# tviic2d6mddr register map
Vendor: Cypress Semiconductor; Series: tviic2d6mddr; File version: 1.0
CPU: CM7 r0p1, little endian, MPU, FPU, VTOR, 3 interrupt priority bits
Registers are 32-bit, read-write, reset 0x0 unless marked. A register's access mark holds for its fields unless they carry their own. Offsets are from the block's base; [hi:lo] are bit positions; lines under a group give offsets from that group; {n}, {i} and the like mark numbered series.

## JPEGDEC
Base 0x40B10000
0x00 CTL — IP control register.
  [31] ENABLED — IP enable. When the IP is disabled, no other register than this one can be accessed (results in AHB error response). 0: Disabled. 1: Enabled.
0x1000 HF group — Data fetch, store and interrupt control registers.
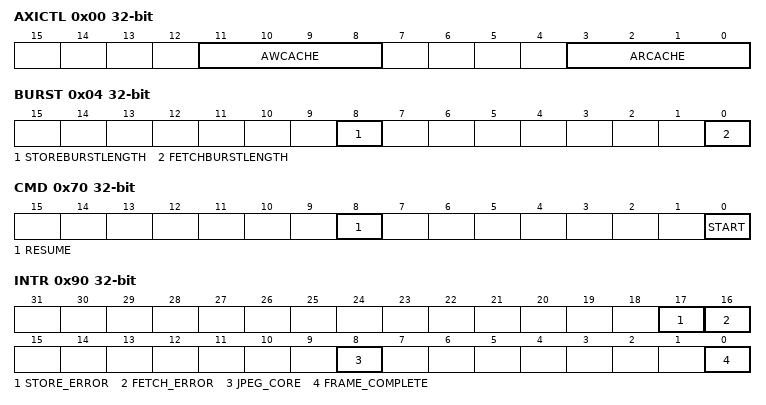
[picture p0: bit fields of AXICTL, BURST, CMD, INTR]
  0x00 AXICTL — AXI cache attributes.
    [11:8] AWCACHE — AWCACHE value of AXI transactions on Store Unit. Must not be changed during decoding operation.
    [3:0] ARCACHE — ARCACHE value of AXI transactions on Fetch Unit. Must not be changed during decoding operation.
  0x04 BURST — AXI burst settings.
    [8] STOREBURSTLENGTH — Maximum burst length for Store Unit. Must not be changed during decoding operation. 0: Length is 4 1: Length is 8
    [0] FETCHBURSTLENGTH — Maximum burst length for Fetch Unit. Must not be changed during decoding operation. 0: Length is 4 1: Length is 8
  0x10 FETCHBUF0 — Source buffer configuration (JPEG).
    [31:0] FETCHBASEADDRESS — Start address of the JPEG image in bytes. There are no alignment restrictions, however, read access to memory is 32- or 64-byte aligned, depending on configured burst length. So reading ahead of the actual start address must be allowed, if it is not aligned accordingly. RWS field, which is activated by START command.
  0x14 FETCHBUF1 — Source buffer configuration (JPEG).
    [29:0] FETCHLENGTH — JPEG image length in bytes. There are no alignment restrictions, however, read access to memory is 32- or 64-byte aligned, depending on the configured burst length. So reading beyond the actual end address must be allowed, if it is not aligned accordingly. RWS field, which is activated by START command.
  0x20 STORE0BUF0 — Destination buffer configuration (Y, YUV, RGB).
    [31:6] STOREBASEADDRESS0 — Start address of the destination buffer 0 in multiple of 64 bytes. The destination buffer 0 holds the YUV or RGB pixels for packed format and Y pixels only for semi-planar format. RWS field, which is activated by START or RESUME command.
  0x24 STORE0BUF1 — Destination buffer configuration (Y, YUV, RGB).
    [31:6] STORESTRIDE0 — Line stride of the destination buffer 0 in multiple of 64 bytes. RWS field, which is activated by START or RESUME command.
  0x28 STORE0BUF2 — Destination buffer configuration (Y, YUV, RGB).
    [31:6] STORELENGTH0 — Destination buffer 0 length in multiple of 64 bytes. RWS field, which is activated by START or RESUME command.
  0x40 STORE1BUF0 — Destination buffer configuration (UV).
    [31:6] STOREBASEADDRESS1 — Start address of the destination buffer 1 in multiple of 64 bytes. The destination buffer 1 holds UV pixels for semi-planar format. RWS field, which is activated by START or RESUME command.
  0x44 STORE1BUF1 — Destination buffer configuration (UV).
    [31:6] STORESTRIDE1 — Line stride of the destination buffer 1 in multiple of 64 bytes.RWS field, which is activated by START or RESUME command.
  0x48 STORE1BUF2 — Destination buffer configuration (UV).
    [31:6] STORELENGTH1 — Destination buffer 1 length in multiple of 64 bytes. RWS field, which is activated by START or RESUME command.
  0x60 STORECTL — Destination buffer format settings.
    [0] UPSAMPLING — Decoded pixels are up-sampled to YUV 4:4:4. If the sub-sampling mode in the encoded JPEG data is NOT YUV 4:2:2, YUV 4:1:1 or YUV 4:2:0, this field is ignored. RWS field, which is activated by START or RESUME command.
  0x70 CMD — Start/Resume triggers.
    [8] RESUME — Writing '1' to this register will activate store related shadow configuration (RWS) and then resume a suspended decoding operation.
    [0] START — Writing '1' to this register will activate fetch and store related shadow configuration (RWS) and then start a new decoding operation. The following registers are initialized by this operation: ERRORSTATUS STORESTATUS FETCHSTATUS DECODINGSTATUS INTR_DEC ERRORCODE CORRECTIONCROPSTATUS SUSPEND DNL DRI (only if DECODINGOPTION.MARKERSKIP=0) All Huffman Tables (only if DECODINGOPTION.MARKERSKIP=0)
  0x80 DECODEINTRMASK — Decoder core decoding end interrupt mask.
    [0] DECODEINTRMASK — Setting this bit to '1' propagates decoding completion status (INTR_DEC.NORMALEND/INTR_DEC.CORRECTEDEND ORed) to INTR.JPEG_CORE.
  0x90 INTR — Interrupt status bits.
    [17] STORE_ERROR — HW sets this field to '1' when there is an error in the on-going AXI transaction on store side (i.e. when one of ERRORSTATUS fields is set). Read ERRORSTATUS to see what event set this bit.
    [16] FETCH_ERROR — HW sets this field to '1' when there is an error in the on-going AXI transaction on fetch side (i.e. when one of ERRORSTATUS fields is set). Read ERRORSTATUS to see what event set this bit.
    [8] JPEG_CORE — HW sets this field to '1' when a flag in INTR_DEC is set with corresponding propagation field enabled (DECODEINTRMASK or INTR_DEC_EN). See description of INTR_DEC_EN/DECODEINTRMASK for more detail.
    [0] FRAME_COMPLETE — This interrupt occurs when Store Unit finishes storing all pixels in the destination.
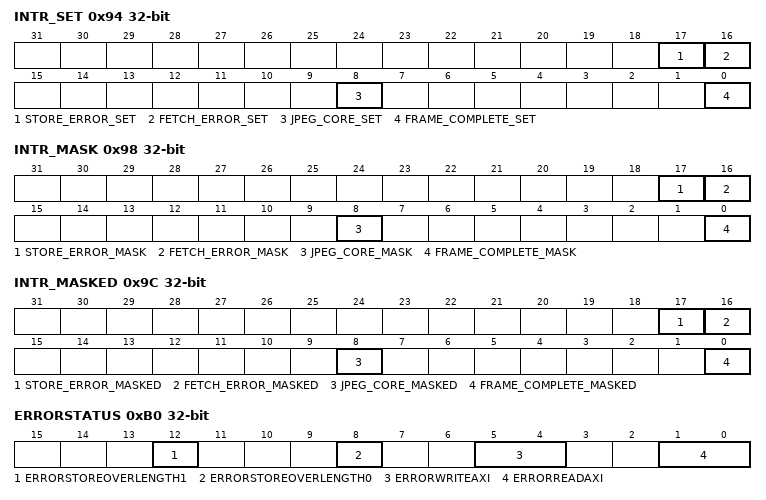
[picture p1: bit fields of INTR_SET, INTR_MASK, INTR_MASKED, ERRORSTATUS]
  0x94 INTR_SET — Interrupt set bits.
    [17] STORE_ERROR_SET — Write this field with '1' to set corresponding INTR field (a write of '0' has no effect).
    [16] FETCH_ERROR_SET — Write this field with '1' to set corresponding INTR field (a write of '0' has no effect).
    [8] JPEG_CORE_SET — Write this field with '1' to set corresponding INTR field (a write of '0' has no effect).
    [0] FRAME_COMPLETE_SET — Write this field with '1' to set corresponding INTR field (a write of '0' has no effect).
  0x98 INTR_MASK — Interrupt mask bits.
    [17] STORE_ERROR_MASK — Mask for corresponding field in INTR register.
    [16] FETCH_ERROR_MASK — Mask for corresponding field in INTR register.
    [8] JPEG_CORE_MASK — Mask for corresponding field in INTR register.
    [0] FRAME_COMPLETE_MASK — Mask for corresponding field in INTR register.
  0x9C INTR_MASKED ro — Interrupt masked bits.
    [17] STORE_ERROR_MASKED — Logical AND of corresponding INTR and INTR_MASK fields.
    [16] FETCH_ERROR_MASKED — Logical AND of corresponding INTR and INTR_MASK fields.
    [8] JPEG_CORE_MASKED — Logical AND of corresponding INTR and INTR_MASK fields.
    [0] FRAME_COMPLETE_MASKED — Logical AND of corresponding INTR and INTR_MASK fields.
  0xB0 ERRORSTATUS ro
    [12] ERRORSTOREOVERLENGTH1 — The decoded pixel data is overflowed from the region defined in StoreLength1. The decoding operation is stopped and cannot be resumed.
    [8] ERRORSTOREOVERLENGTH0 — The decoded pixel data is overflowed from the region defined in StoreLength0. The decoding operation is stopped and cannot be resumed.
    [5:4] ERRORWRITEAXI
    [1:0] ERRORREADAXI
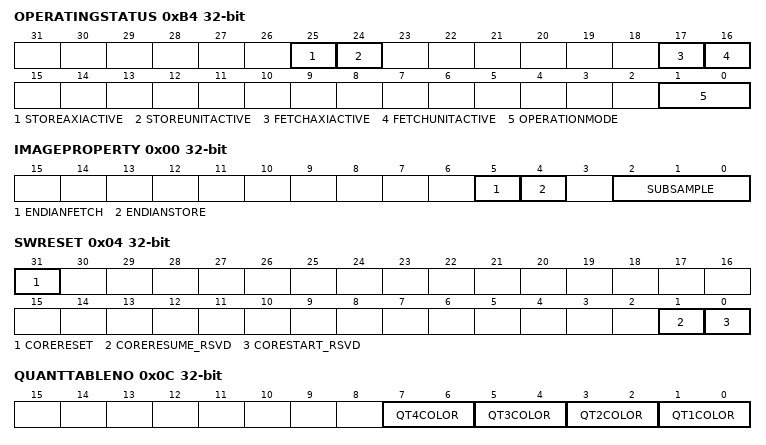
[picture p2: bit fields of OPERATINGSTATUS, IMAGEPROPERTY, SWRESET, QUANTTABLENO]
  0xB4 OPERATINGSTATUS ro
    [25] STOREAXIACTIVE — There is an active AXI write transaction by Store Unit
    [24] STOREUNITACTIVE — Store Unit is operating.
    [17] FETCHAXIACTIVE — There is an active AXI read transaction by Fetch Unit
    [16] FETCHUNITACTIVE — Fetch Unit is operating.
    [1:0] OPERATIONMODE
  0xB8 FETCHSTATUS ro — Fetch Unit status.
    [29:0] FETCHBYTES — Number of total fetched bytes.
  0xBC STORESTATUS ro — Store Unit status.
    [29:0] STOREBYTES — Number of total stored bytes (sum of both buffers in case of semi-planar formats).
0x1800 DEC group — JPEG decoder core registers.
  0x00 IMAGEPROPERTY — Image property settings.
    [5] ENDIANFETCH
    [4] ENDIANSTORE
    [2:0] SUBSAMPLE ro — Sub-sampling mode defined in SOF marker segment 000 4:4:4 001 4:2:2 110 4:1:1 010 4:2:0 011 Gray Scale 100 CMYK 111 Invalid
  0x04 SWRESET wo — Software reset trigger.
    [31] CORERESET — Software reset of the JPEG core. Setting this field to '1' initializes the following registers (others are retained): DECODINGSTATUS INTR_DEC ERRORCODE CORRECTIONCROPSTATUS SUSPEND DNL
    [1] CORERESUME_RSVD
    [0] CORESTART_RSVD
  0x08 DECODINGSTATUS ro
    [0] DECODINGSTATUS — Decoding status. 0: Not decoding 1: Decoding
  0x0C QUANTTABLENO ro — Quantization table number downloaded from the JPEG image.
    [7:6] QT4COLOR — Quantization table number of 4th color component
    [5:4] QT3COLOR — Quantization table number of 3rd color component
    [3:2] QT2COLOR — Quantization table number of 2nd color component
    [1:0] QT1COLOR — Quantization table number of 1st color component
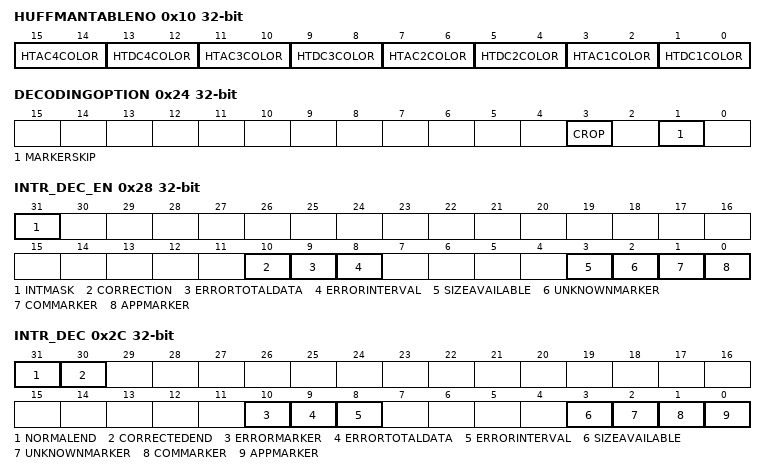
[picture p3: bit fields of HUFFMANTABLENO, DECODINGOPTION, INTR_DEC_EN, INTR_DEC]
  0x10 HUFFMANTABLENO ro — Huffman Table number downloaded from the JPEG image.
    [15:14] HTAC4COLOR — AC Huffman table number of 4th color component
    [13:12] HTDC4COLOR — DC Huffman table number of 4th color component
    [11:10] HTAC3COLOR — AC Huffman table number of 3rd color component
    [9:8] HTDC3COLOR — DC Huffman table number of 3rd color component
    [7:6] HTAC2COLOR — AC Huffman table number of 2nd color component
    [5:4] HTDC2COLOR — DC Huffman table number of 2nd color component
    [3:2] HTAC1COLOR — AC Huffman table number of 1st color component
    [1:0] HTDC1COLOR — DC Huffman table number of 1st color component
  0x14 DRI ro — The DRI value downloaded from the JPEG image.
    [15:0] DRI — Value downloaded from DRI marker segment.
  0x18 SIZEY ro — Y size downloaded from the JPEG image.
    [15:0] SIZEY — Y size value downloaded from SOF marker segment.
  0x1C SIZEX ro — X size downloaded from the JPEG image.
    [15:0] SIZEX — X size value downloaded from SOF marker segment.
  0x24 DECODINGOPTION — Decoding option settings.
    [3] CROP — This bit enables Crop Function. 0: disable 1: enable
    [1] MARKERSKIP — This bit enables Marker Skip Function. 0: disable 1: enable
  0x28 INTR_DEC_EN — Interrupt Setting
    [31] INTMASK — This field is a global mask for the propagation of INTR_DEC bits to INTR.JPEG_CORE. This field has following polarity: 0: enable propagation 1: disable propagation
    [10] CORRECTION — This bit enables Correction Function.
    [9] ERRORTOTALDATA — Setting this bit to '1' propagates the corresponding INTR_DEC bit to INTR.JPEG_CORE.
    [8] ERRORINTERVAL — Setting this bit to '1' propagates the corresponding INTR_DEC bit to INTR.JPEG_CORE.
    [3] SIZEAVAILABLE — Setting this bit to '1' propagates the corresponding INTR_DEC bit to INTR.JPEG_CORE.
    [2] UNKNOWNMARKER — Setting this bit to '1' propagates the corresponding INTR_DEC bit to INTR.JPEG_CORE.
    [1] COMMARKER — Setting this bit to '1' propagates the corresponding INTR_DEC bit to INTR.JPEG_CORE.
    [0] APPMARKER — Setting this bit to '1' propagates the corresponding INTR_DEC bit to INTR.JPEG_CORE.
  0x2C INTR_DEC — Interrupt status
    [31] NORMALEND — HW sets this field to '1' when the JPEG decoder core has finished normally.
    [30] CORRECTEDEND — HW sets this field to '1' when the JPEG decoder core has finished decoding with Correction Mode taking effect. Register CORRECTIONCROPSTATUS shows more detailed status of how Correction Mode has corrected the original image.
    [10] ERRORMARKER — HW sets this field to '1' when the JPEG decoder core has stopped decoding due to a marker-related problem. Read ERRORCODE register to find what caused this bit to be set.
    [9] ERRORTOTALDATA — HW sets this field to '1' when the number of data in Huffman coding segment from SOS to EOI is different from the value defined in the SOF marker segment.
    [8] ERRORINTERVAL — HW sets this field to '1' when the interval between RSTm markers is different from the value defined in the DRI marker segment.
    [3] SIZEAVAILABLE — HW sets this field to '1' when the JPEG decoder core has stored the x/y size and the sub-sampling mode of the JPEG image into SizeX/SizeY registers and ImageProperty register.
    [2] UNKNOWNMARKER — HW sets this field to '1' when a marker that cannot be processed by the JPEG decoder core (markers other than SOI/SOS/DQT/DHT/DRI/RSTm/EOI/SOF0 to SOFF/APPn/COM/TEM) is detected in the JPEG image.
    [1] COMMARKER — HW sets this field to '1' when a COM marker is detected in the JPEG image.
    [0] APPMARKER — HW sets this field to '1' when an APP marker is detected in the JPEG image.
  0x30 ERRORCODE ro reset 0x1 — Error code for INTR_DEC.ErrorMarker.
    [5:0] ERRORCODE — This field indicates the cause for the error interrupt for markers (INTR_DEC.ERRORMARKER).
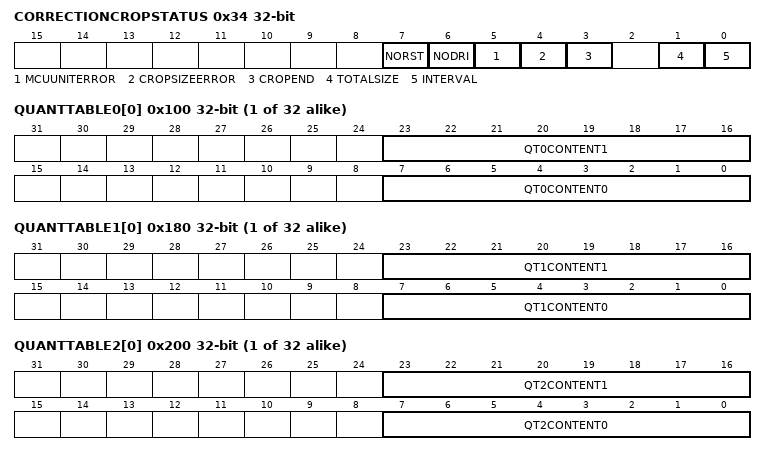
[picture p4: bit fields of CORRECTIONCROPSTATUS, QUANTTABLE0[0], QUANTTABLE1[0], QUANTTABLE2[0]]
  0x34 CORRECTIONCROPSTATUS ro — Correction Mode and Crop Decoding status. This register is initialized by the decoding start trigger (CMD.START).
    [7] NORST — The crop region specified in CROPSTARTX/Y and CROPSIZEX/Y doesn't have a RSTm marker at the end of each line. When this error occurs, the decoding is stopped immediately, and the normal end status is flagged (INTR_DEC.NORMALEND='1').
    [6] NODRI — DRI marker is missing in the JPEG image. When this error occurs, a normal decoding without crop is performed and flags the normal end status (INTR_DEC.NORMALEND='1') when complete.
    [5] MCUUNITERROR — Crop has been cancelled since the crop region specified in CROPSTARTX/Y and CROPSIZEX/Y doesn't end at the MCU boundary. When this error occurs, a normal decoding without crop is performed and flags the normal end status (INTR_DEC.NORMALEND='1') when complete.
    [4] CROPSIZEERROR — Crop has been cancelled due to the illegal crop region specified in CROPSTARTX/Y and CROPSIZEX/Y. When this error occurs, a normal decoding without crop is performed and flags the normal end status (INTR_DEC.NORMALEND='1') when complete.
    [3] CROPEND — Crop has finished successfully.
    [1] TOTALSIZE — Pixels exceeding the total image size defined in the SOF segment have been discarded.
    [0] INTERVAL — Huffman coding segment data exceeding the DRI have been discarded.
  0x38 SUSPEND ro — Suspend status. Decoding can be resumed from Suspended State by writing '1' to CMD.RESUME.
    [0] SUSPEND — This bit indicates whether the JPEG decoder core has been suspended due to detection of an APP/COM/unknown marker or the size/sub-sampling information in the JPEG header. 0: Not suspended 1: Suspended due to detection of an APP/COM/unknown marker or the size/sub-sampling
  0x3C DNL ro — DNL value downloaded from the JPEG image. This register is initialized by the decoding start trigger (CMD.START).
    [15:0] DNL — DNL value defined in the marker
  0x40 CROPSTARTY — Y crop start position
    [15:0] CROPSTARTY
  0x44 CROPSTARTX — X crop start position
    [15:0] CROPSTARTX
  0x48 CROPSIZEY — Crop size for Y direction
    [15:0] CROPSIZEY
  0x4C CROPSIZEX — Crop size for X direction
    [15:0] CROPSIZEX
  {0x100+4j} QUANTTABLE0[{j}] (j=0..31) ro reset not defined — Quantization Table number 0 downloaded from a JPEG image.
    [23:16] QT0CONTENT1 — An entry in Quantization Table 0
    [7:0] QT0CONTENT0 — An entry in Quantization Table 0
  {0x180+4j} QUANTTABLE1[{j}] (j=0..31) ro reset not defined — Quantization Table number 1 downloaded from a JPEG image.
    [23:16] QT1CONTENT1 — An entry in Quantization Table 1
    [7:0] QT1CONTENT0 — An entry in Quantization Table 1
  {0x200+4j} QUANTTABLE2[{j}] (j=0..31) ro reset not defined — Quantization Table number 2 downloaded from a JPEG image.
    [23:16] QT2CONTENT1 — An entry in Quantization Table 2
    [7:0] QT2CONTENT0 — An entry in Quantization Table 2
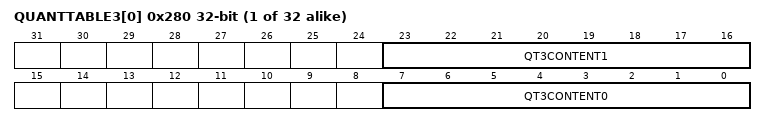
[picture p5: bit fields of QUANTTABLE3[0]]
  {0x280+4j} QUANTTABLE3[{j}] (j=0..31) ro reset not defined — Quantization Table number 3 downloaded from a JPEG image.
    [23:16] QT3CONTENT1 — An entry in Quantization Table 2
    [7:0] QT3CONTENT0 — An entry in Quantization Table 2
  {0x300+4j} HUFFMANTABLEDC0CODELENGTH[{j}] (j=0..3) ro — Shows the code length distribution for DC Huffman Table 0. For each Huffman code lengths (0 to 16), the number of used codes is shown. e.g. Field for code length 3 has the value '5' when 010/011/100/101/110 are used.
    [31:0] DC0NUMCODELENGTHN — Number of codes with the code length of n (n=1~16) in DC Huffman Table 0.
  {0x310+4j} HUFFMANTABLEDC0GROUPNO[{j}] (j=0..2) ro reset 0xF0F0F0F — Shows the group numbers in the order of descending appearance frequencies for DC Huffman Table 0.
    [31:0] DC0GROUPNO
  {0x320+4j} HUFFMANTABLEAC0CODELENGTH[{j}] (j=0..3) ro — Shows the code length distribution for AC Huffman Table 0. For each Huffman code lengths (0 to 16), the number of used codes is shown. e.g. Field for code length 3 has the value '5' when 010/011/100/101/110 are used.
    [31:0] AC0NUMCODELENGTHN — Number of codes with the code length of n (n=1~16) in AC Huffman Table 0.
  {0x330+4j} HUFFMANTABLEAC0GROUPNO[{j}] (j=0..40) ro reset 0xFFFFFFFF — Shows the zero run-length+group number values in the order of descending appearance frequencies for AC Huffman Table 0.
    [31:0] AC0GROUPNO — Shows the zero run-length+group number values in the order of descending appearance frequencies for AC Huffman Table 0. Note: For the last word (offset 0x3D0), only upper half-word is used. Its default value is 0xFFFF0000.
  {0x414+4j} HUFFMANTABLEDC1CODELENGTH[{j}] (j=0..3) ro — Shows the code length distribution for DC Huffman Table 1. For each Huffman code lengths (0 to 16), the number of used codes is shown. e.g. Field for code length 3 has the value '5' when 010/011/100/101/110 are used.
    [31:0] DC1NUMCODELENGTHN — Number of codes with the code length of n (n=1~16) in DC Huffman Table 1.
  {0x424+4j} HUFFMANTABLEDC1GROUPNO[{j}] (j=0..2) ro reset 0xF0F0F0F — Shows the group numbers in the order of descending appearance frequencies for DC Huffman Table 1.
    [31:0] DC1GROUPNO
  {0x434+4j} HUFFMANTABLEAC1CODELENGTH[{j}] (j=0..3) ro — Shows the code length distribution for AC Huffman Table 1. For each Huffman code lengths (0 to 16), the number of used codes is shown. e.g. Field for code length 3 has the value '5' when 010/011/100/101/110 are used.
    [31:0] AC1NUMCODELENGTHN — Number of codes with the code length of n (n=1~16) in AC Huffman Table 1.
  {0x444+4j} HUFFMANTABLEAC1GROUPNO[{j}] (j=0..40) ro reset 0xFFFFFFFF — Shows the zero run-length+group number values in the order of descending appearance frequencies for AC Huffman Table 1.
    [31:0] AC1GROUPNO — Shows the zero run-length+group number values in the order of descending appearance frequencies for AC Huffman Table 1. Note: For the last word (offset 0x4E4), only upper half-word is used. Its default value is 0xFFFF0000.
